VERSION "HIPBNYYYYYYYYYYYYYYYYYYYYYYYYYYYYYYYYYYYYY/4/%%%/4/'%**4YYY///"

NS_ :

BS_:

BU_: ME_AWS_CANA
VAL_TABLE_ Vt_Float_Parameter_Unit 5 "MInute" 4 "Second" 3 "Feet" 2 "Meter" 1 "MPH" 0 "KMH" ;
VAL_TABLE_ Vt_Duration_Unit 3 "hour" 2 "minute" 1 "10_seconds" 0 "second" ;
VAL_TABLE_ Vt_ON_OFF 1 "on" 0 "off" ;

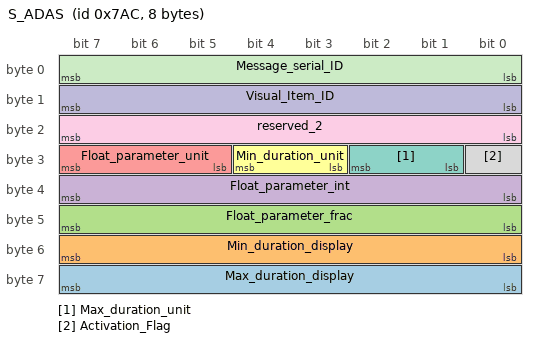
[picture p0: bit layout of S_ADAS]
BO_ 1964 S_ADAS: 8 ME_AWS_CANA
 SG_ Max_duration_display : 56|8@1+ (1,0) [0|255] "" Vector__XXX
 SG_ Min_duration_display : 48|8@1+ (1,0) [0|255] "" Vector__XXX
 SG_ Float_parameter_frac : 40|8@1+ (1,0) [0|255] "" Vector__XXX
 SG_ Float_parameter_int : 32|8@1+ (1,0) [0|255] "" Vector__XXX
 SG_ Float_parameter_unit : 29|3@1+ (1,0) [0|7] "enum" Vector__XXX
 SG_ Min_duration_unit : 27|2@1+ (1,0) [0|3] "enum" Vector__XXX
 SG_ Max_duration_unit : 25|2@1+ (1,0) [0|3] "enum" Vector__XXX
 SG_ Activation_Flag : 24|1@1- (1,0) [0|1] "bool" Vector__XXX
 SG_ reserved_2 : 16|8@1- (1,0) [0|0] "" Vector__XXX
 SG_ Visual_Item_ID : 8|8@1+ (1,0) [1|255] "" Vector__XXX
 SG_ Message_serial_ID : 0|8@1+ (1,0) [1|255] "" Vector__XXX

VAL_ 1964 Float_parameter_unit 5 "MInute" 4 "Second" 3 "Feet" 2 "Meter" 1 "MPH" 0 "KMH" ;
VAL_ 1964 Min_duration_unit 3 "hour" 2 "minute" 1 "10_seconds" 0 "second" ;
VAL_ 1964 Max_duration_unit 3 "hour" 2 "minute" 1 "10_seconds" 0 "second" ;
